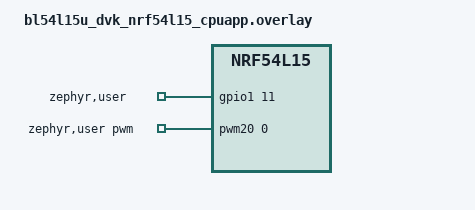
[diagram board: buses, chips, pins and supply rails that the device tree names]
/*
 * Copyright (c) 2024 Nordic Semiconductor ASA
 * Copyright (c) 2025 Ezurio LLC
 * SPDX-License-Identifier: Apache-2.0
 *
 * Test requires jumper between:
 *  - PWM20 OUT[0] at P1.10 <-> GPIO input at P1.11
 */

/ {
	zephyr,user {
		pwms = <&pwm20 0 160000 PWM_POLARITY_NORMAL>;
		gpios = <&gpio1 11 GPIO_ACTIVE_HIGH>;
	};
};
